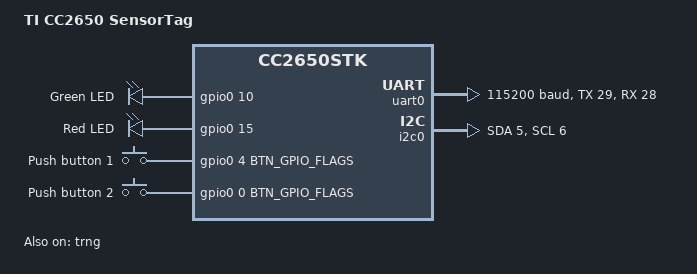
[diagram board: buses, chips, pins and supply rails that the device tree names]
/*
 * Copyright (c) 2019 Brett Witherspoon
 *
 * SPDX-License-Identifier: Apache-2.0
 */

/dts-v1/;

#include <ti/cc2650.dtsi>

#define BTN_GPIO_FLAGS (GPIO_INT_ACTIVE_LOW | GPIO_PUD_PULL_UP)

/ {
	model = "TI CC2650 SensorTag";
	compatible = "ti,cc2650-sensortag", "ti,cc2650stk";

	aliases {
		led0 = &led0;
		led1 = &led1;
		sw0 = &btn0;
		sw1 = &btn1;
	};

	chosen {
		zephyr,sram = &sram0;
		zephyr,flash = &flash0;
		zephyr,console = &uart0;
		zephyr,shell-uart = &uart0;
	};

	leds {
		compatible = "gpio-leds";
		led0: led_0 {
			gpios = <&gpio0 10 0>;
			label = "Green LED";
		};
		led1: led_1 {
			gpios = <&gpio0 15 0>;
			label = "Red LED";
		};
	};

	keys {
		compatible = "gpio-keys";
		btn0: btn_0 {
			gpios = <&gpio0 4 BTN_GPIO_FLAGS>;
			label = "Push button 1";
		};
		btn1: btn_1 {
			gpios = <&gpio0 0 BTN_GPIO_FLAGS>;
			label = "Push button 2";
		};
	};
};

&trng {
	status = "ok";
};

&gpio0 {
	status = "ok";
};

devpack_uart: &uart0 {
	status = "ok";
	current-speed = <115200>;
	tx-pin = <29>;
	rx-pin = <28>;
};

devpack_i2c: &i2c0 {
	status = "ok";
	scl-pin = <6>;
	sda-pin = <5>;
};
